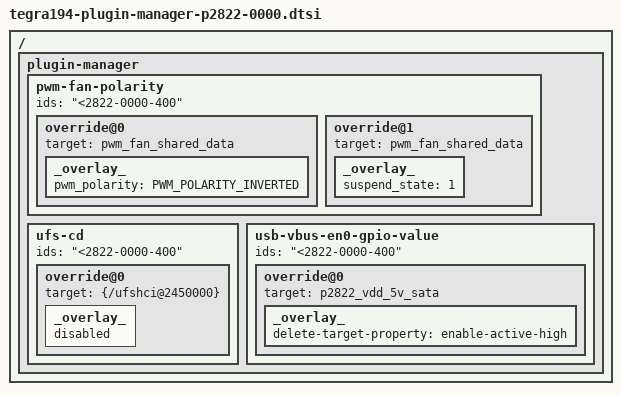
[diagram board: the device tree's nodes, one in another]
/*
 * Copyright (c) 2018-2020, NVIDIA CORPORATION.  All rights reserved.
 *
 * This program is free software; you can redistribute it and/or modify it
 * under the terms and conditions of the GNU General Public License,
 * version 2, as published by the Free Software Foundation.
 *
 * This program is distributed in the hope it will be useful, but WITHOUT
 * ANY WARRANTY; without even the implied warranty of MERCHANTABILITY or
 * FITNESS FOR A PARTICULAR PURPOSE.  See the GNU General Public License for
 * more details.
 *
 * You should have received a copy of the GNU General Public License
 * along with this program.  If not, see <http://www.gnu.org/licenses/>.
 */
#include <dt-bindings/pwm/pwm.h>

/ {
	plugin-manager {
		pwm-fan-polarity {
			ids = "<2822-0000-400";
			override@0 {
				target = <&pwm_fan_shared_data>;
				_overlay_ {
					pwm_polarity = <PWM_POLARITY_INVERTED>;
				};
			};
			override@1 {
				target = <&pwm_fan_shared_data>;
				_overlay_ {
					suspend_state = <1>;
				};
			};
		};

		ufs-cd {
			ids = "<2822-0000-400";
			override@0 {
				target = <&{/ufshci@2450000}>;
				_overlay_ {
				    status = "disabled";
				};
			};
		};

		usb-vbus-en0-gpio-value {
			ids = "<2822-0000-400";
			override@0 {
				target = <&p2822_vdd_5v_sata>;
				_overlay_ {
					delete-target-property = "enable-active-high";
				};
			};
		};
	};
};
